AUTOSAR XML (schema 4-0-3)
package /ComponentTypes
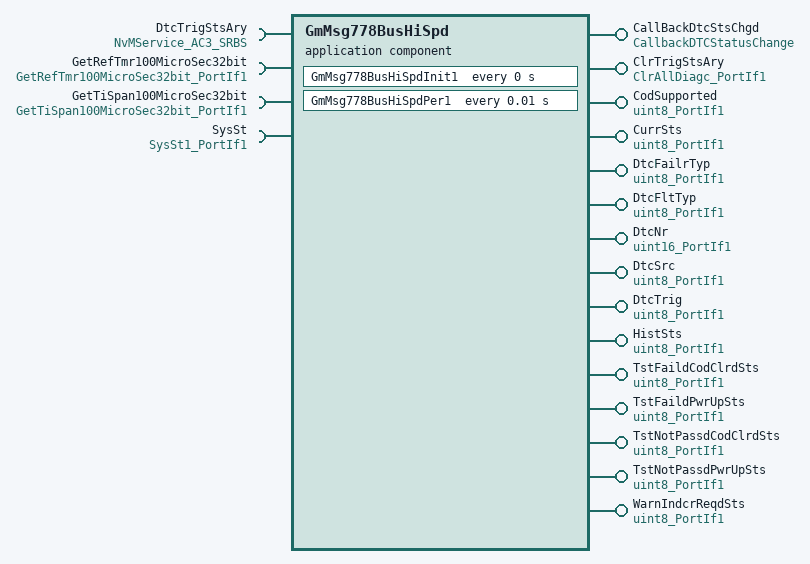
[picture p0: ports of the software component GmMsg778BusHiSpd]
  application sw component type GmMsg778BusHiSpd
    15 x provide port:
      CallBackDtcStsChgd: server-com-spec{operation=DTCStatusChanged, queue-length=1}, provided-interface=CallbackDTCStatusChange
      ClrTrigStsAry: server-com-spec{operation=Oper, queue-length=1}, provided-interface=ClrAllDiagc_PortIf1
      CodSupported: nonqueued-sender-com-spec{data-element=Val, init-value=0}, provided-interface=uint8_PortIf1
      CurrSts: nonqueued-sender-com-spec{data-element=Val, init-value=0}, provided-interface=uint8_PortIf1
      DtcFailrTyp: nonqueued-sender-com-spec{data-element=Val, init-value=0}, provided-interface=uint8_PortIf1
      DtcFltTyp: nonqueued-sender-com-spec{data-element=Val, init-value=0}, provided-interface=uint8_PortIf1
      DtcNr: nonqueued-sender-com-spec{data-element=Val, init-value=0}, provided-interface=uint16_PortIf1
      DtcSrc: nonqueued-sender-com-spec{data-element=Val, init-value=0}, provided-interface=uint8_PortIf1
      DtcTrig: nonqueued-sender-com-spec{data-element=Val, init-value=0}, provided-interface=uint8_PortIf1
      HistSts: nonqueued-sender-com-spec{data-element=Val, init-value=0}, provided-interface=uint8_PortIf1
      TstFaildCodClrdSts: nonqueued-sender-com-spec{data-element=Val, init-value=0}, provided-interface=uint8_PortIf1
      TstFaildPwrUpSts: nonqueued-sender-com-spec{data-element=Val, init-value=0}, provided-interface=uint8_PortIf1
      TstNotPassdCodClrdSts: nonqueued-sender-com-spec{data-element=Val, init-value=0}, provided-interface=uint8_PortIf1
      TstNotPassdPwrUpSts: nonqueued-sender-com-spec{data-element=Val, init-value=0}, provided-interface=uint8_PortIf1
      WarnIndcrReqdSts: nonqueued-sender-com-spec{data-element=Val, init-value=0}, provided-interface=uint8_PortIf1
    4 x require port:
      DtcTrigStsAry: required-interface=NvMService_AC3_SRBS
      GetRefTmr100MicroSec32bit: required-interface=GetRefTmr100MicroSec32bit_PortIf1
      GetTiSpan100MicroSec32bit: required-interface=GetTiSpan100MicroSec32bit_PortIf1
      SysSt: nonqueued-receiver-com-spec{data-element=Val, filter=data-filter-type=ALWAYS, init-value=3}, required-interface=SysSt1_PortIf1
    behavior GmMsg778BusHiSpd_InternalBehavior: data-type-mapping=Nexteer
      ar-typed-per-instance-memorys:
        7 x data, all with sw-calibration-access=READ-ONLY:
          ActvEveId: type=uint8
          DtcMap: type=Ary1D_u32_40
          DtcTrigStsAry: type=Ary1D_u8_40
          EveCnt: type=uint8
          EveMap: type=Ary1D_u8_40
          TrigActv: type=boolean
          TrigTmr: type=uint32
      operation invoked event OIT_CallbackDTCStatusChange_DTCStatusChanged_CallbackDTCStatusChange_DTCStatusChanged: start-on-event=CallBackDtcStsChgd, operation=CallBackDtcStsChgd.DTCStatusChanged
      operation invoked event OIT_ClrTrigStsAry_Oper_ClrTrigStsAry_Oper: start-on-event=ClrTrigStsAry_Oper, operation=ClrTrigStsAry.Oper
      timing event GmMsg778BusHiSpd_InitEvent: start-on-event=GmMsg778BusHiSpdInit1, period=0
      timing event TMT_GM0C9HSPer1: start-on-event=GmMsg778BusHiSpdPer1, period=0.01
      4 x runnable:
        CallBackDtcStsChgd
        ClrTrigStsAry_Oper
          data-receive-point-by-arguments:
            access REC_SysSt_Val: accessed-variable=SysSt.Val
          data-send-points:
            13 x access:
              SEND_CodSupported_Val: accessed-variable=CodSupported.Val
              SEND_CurrSts_Val: accessed-variable=CurrSts.Val
              SEND_DtcFailrTyp_Val: accessed-variable=DtcFailrTyp.Val
              SEND_DtcFltTyp_Val: accessed-variable=DtcFltTyp.Val
              SEND_DtcNr_Val: accessed-variable=DtcNr.Val
              SEND_DtcSrc_Val: accessed-variable=DtcSrc.Val
              SEND_DtcTrig_Val: accessed-variable=DtcTrig.Val
              SEND_HistSts_Val: accessed-variable=HistSts.Val
              SEND_TstFaildCodClrdSts_Val: accessed-variable=TstFaildCodClrdSts.Val
              SEND_TstFaildPwrUpSts_Val: accessed-variable=TstFaildPwrUpSts.Val
              SEND_TstNotPassdCodClrdSts_Val: accessed-variable=TstNotPassdCodClrdSts.Val
              SEND_TstNotPassdPwrUpSts_Val: accessed-variable=TstNotPassdPwrUpSts.Val
              SEND_WarnIndcrReqdSts_Val: accessed-variable=WarnIndcrReqdSts.Val
        GmMsg778BusHiSpdInit1
          data-receive-point-by-arguments:
            access REC_SysSt_Val: accessed-variable=SysSt.Val
          data-send-points:
            13 x access:
              SEND_CodSupported_Val: accessed-variable=CodSupported.Val
              SEND_CurrSts_Val: accessed-variable=CurrSts.Val
              SEND_DtcFailrTyp_Val: accessed-variable=DtcFailrTyp.Val
              SEND_DtcFltTyp_Val: accessed-variable=DtcFltTyp.Val
              SEND_DtcNr_Val: accessed-variable=DtcNr.Val
              SEND_DtcSrc_Val: accessed-variable=DtcSrc.Val
              SEND_DtcTrig_Val: accessed-variable=DtcTrig.Val
              SEND_HistSts_Val: accessed-variable=HistSts.Val
              SEND_TstFaildCodClrdSts_Val: accessed-variable=TstFaildCodClrdSts.Val
              SEND_TstFaildPwrUpSts_Val: accessed-variable=TstFaildPwrUpSts.Val
              SEND_TstNotPassdCodClrdSts_Val: accessed-variable=TstNotPassdCodClrdSts.Val
              SEND_TstNotPassdPwrUpSts_Val: accessed-variable=TstNotPassdPwrUpSts.Val
              SEND_WarnIndcrReqdSts_Val: accessed-variable=WarnIndcrReqdSts.Val
          sync call SC_DtcTrigStsAry_SetRamBlockStatus: operation=DtcTrigStsAry.SetRamBlockStatus, timeout=0
        GmMsg778BusHiSpdPer1
          data-receive-point-by-arguments:
            access REC_SysSt_Val: accessed-variable=SysSt.Val
          data-send-points:
            13 x access:
              SEND_CodSuprd_Val: accessed-variable=CodSupported.Val
              SEND_CurrSts_Val: accessed-variable=CurrSts.Val
              SEND_DtcFailrTyp_Val: accessed-variable=DtcFailrTyp.Val
              SEND_DtcFltTyp_Val: accessed-variable=DtcFltTyp.Val
              SEND_DtcNr_Val: accessed-variable=DtcNr.Val
              SEND_DtcSrc_Val: accessed-variable=DtcSrc.Val
              SEND_DtcTrig_Val: accessed-variable=DtcTrig.Val
              SEND_HistSts_Val: accessed-variable=HistSts.Val
              SEND_TstFaildCodClrdSts_Val: accessed-variable=TstFaildCodClrdSts.Val
              SEND_TstFaildPwrUpSts_Val: accessed-variable=TstFaildPwrUpSts.Val
              SEND_TstNotPassdCodClrdSts_Val: accessed-variable=TstNotPassdCodClrdSts.Val
              SEND_TstNotPassdPwrUpSts_Val: accessed-variable=TstNotPassdPwrUpSts.Val
              SEND_WarnIndcrReqdSts_Val: accessed-variable=WarnIndcrReqdSts.Val
          sync call SC_GetRefTmr100MicroSec32bit_Oper: operation=GetRefTmr100MicroSec32bit.Oper, timeout=0
          sync call SC_GetTiSpan100MicroSec32bit_Oper: operation=GetTiSpan100MicroSec32bit.Oper, timeout=0
      swc service dependency NvmDtcTrigStsAry: assigned-datas=role-based-data-assignment={role=ramBlock, used-data-element=DtcTrigStsAry}
        assigned-ports:
          port-prototype=DtcTrigStsAry, role=NvMService_AC3_SRBS
          port-prototype=DtcTrigStsAry, role=NvMService_AC3_SRBS
        service-needs:
          nv block needs NvmDtcTrigStsAry: n-data-sets=0, readonly=false, reliability=NO-PROTECTION, resistant-to-changed-sw=true, restore-at-start=true, store-at-shutdown=true
  swc implementation GmMsg778BusHiSpd_Implementation: behavior=GmMsg778BusHiSpd_InternalBehavior
    code-descriptors:
      code Default: artifact-descriptors=autosar-engineering-object={short-label=Default, category=SWSRC}
